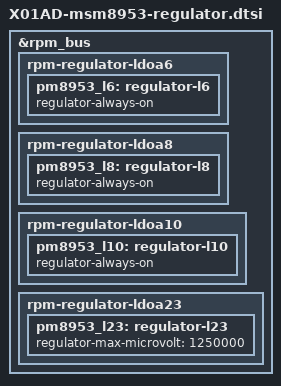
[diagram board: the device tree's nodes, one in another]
/*
 * Copyright (c) 2015-2018, The Linux Foundation. All rights reserved.
 *
 * This program is free software; you can redistribute it and/or modify
 * it under the terms of the GNU General Public License version 2 and
 * only version 2 as published by the Free Software Foundation.
 *
 * This program is distributed in the hope that it will be useful,
 * but WITHOUT ANY WARRANTY; without even the implied warranty of
 * MERCHANTABILITY or FITNESS FOR A PARTICULAR PURPOSE.  See the
 * GNU General Public License for more details.
 */

&rpm_bus {
	rpm-regulator-ldoa6 {
		pm8953_l6: regulator-l6 {
			regulator-always-on;
		};
	};

	rpm-regulator-ldoa8 {
		pm8953_l8: regulator-l8 {
			regulator-always-on;
		};
	};

	rpm-regulator-ldoa10 {
		pm8953_l10: regulator-l10 {
			regulator-always-on;
		};
	};

	rpm-regulator-ldoa23 {
		pm8953_l23: regulator-l23 {
			regulator-max-microvolt = <1250000>;
		};
	};
};
